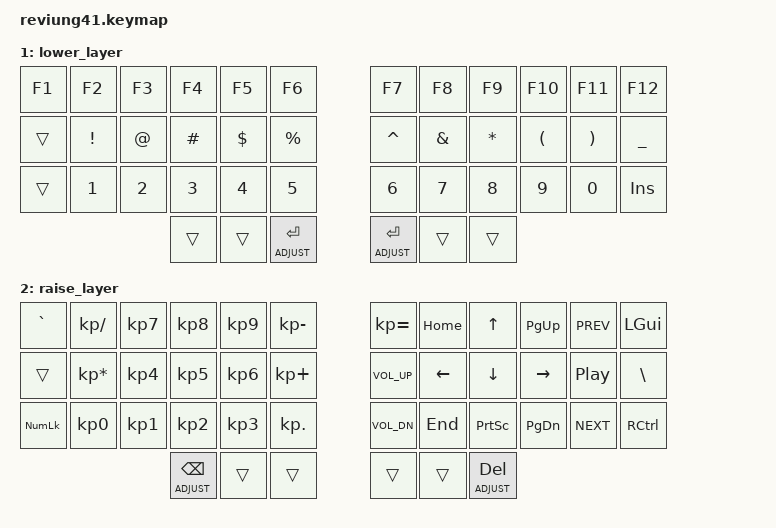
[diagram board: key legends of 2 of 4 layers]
/*
 * Copyright (c) 2020 The ZMK Contributors
 *
 * SPDX-License-Identifier: MIT
 */

#include <behaviors.dtsi>
#include <dt-bindings/zmk/keys.h>
#include <dt-bindings/zmk/bt.h>
#include <dt-bindings/zmk/rgb.h>

#define DEFAULT 0
#define LOWER   1
#define RAISE   2
#define ADJUST  3

&lt { quick_tap_ms = <200>; };
&mt { quick_tap_ms = <200>; };

/ {
        keymap {
                compatible = "zmk,keymap";

                default_layer {
                        bindings = <
   &mt LGUI ESC   &kp Q &kp W &kp E &kp R &kp T   &kp Y &kp U  &kp I     &kp O   &kp P    &mt RGUI LBKT
   &mt LCTRL TAB  &kp A &kp S &kp D &kp F &kp G   &kp H &kp J  &kp K     &kp L   &kp SEMI &kp SQT
   &kp LALT       &kp Z &kp X &kp C &kp V &kp B   &kp N &kp M  &kp COMMA &kp DOT &kp FSLH &mt RCTRL RBKT
   &lt LOWER BSPC  &mt LSHIFT SPACE &lt RAISE ENTER &mt RSHIFT SPACE &lt LOWER DEL
                        >;
                };

                lower_layer {
                        bindings = <
   &kp F1  &kp F2   &kp F3 &kp F4   &kp F5    &kp F6      &kp F7    &kp F8   &kp F9   &kp F10   &kp F11   &kp F12
   &trans  &kp EXCL &kp AT &kp HASH &kp DLLR  &kp PRCNT   &kp CARET &kp AMPS &kp STAR &kp LPAR  &kp RPAR  &kp UNDER
   &trans  &kp N1   &kp N2 &kp N3   &kp N4    &kp N5      &kp N6    &kp N7   &kp N8   &kp N9    &kp N0    &kp INS
                 &trans   &trans    &lt ADJUST ENTER      &lt ADJUST ENTER  &trans   &trans
                        >;
                };

                raise_layer {
                        bindings = <
   &kp GRAVE   &kp KP_SLASH     &kp KP_N7  &kp KP_N8  &kp KP_N9  &kp KP_MINUS    &kp KP_EQUAL  &kp HOME  &kp UP    &kp PG_UP  &kp C_PREV  &kp LGUI
   &trans      &kp KP_ASTERISK  &kp KP_N4  &kp KP_N5  &kp KP_N6  &kp KP_PLUS     &kp C_VOL_UP  &kp LEFT  &kp DOWN  &kp RIGHT  &kp C_PP    &kp BSLH
   &kp KP_NLCK &kp KP_N0        &kp KP_N1  &kp KP_N2  &kp KP_N3  &kp KP_DOT      &kp C_VOL_DN  &kp END   &kp PSCRN &kp PG_DN  &kp C_NEXT  &kp RCTRL
                    	         &lt ADJUST BSPC  &trans   &trans  &trans   &trans    &lt ADJUST DEL
                        >;
                };

                adjust_layer {
                        bindings = <
   &bt BT_CLR      &bt BT_SEL 0    &bt BT_SEL 1    &bt BT_SEL 2    &bt BT_SEL 3  &bt BT_SEL 4    &bt BT_SEL 4 &bt BT_SEL 3 &bt BT_SEL 2 &bt BT_SEL 1 &bt BT_SEL 0 &bt BT_CLR
   &rgb_ug RGB_BRI &rgb_ug RGB_SAI &rgb_ug RGB_HUI &rgb_ug RGB_EFF &none &rgb_ug RGB_TOG    &none        &none        &none        &none        &none        &none
   &rgb_ug RGB_BRD &rgb_ug RGB_SAD &rgb_ug RGB_HUD &rgb_ug RGB_EFR &none &none              &none        &none        &none        &none        &none        &none
                                                             &trans      &trans       &tog 3        &trans      &trans
                        >;
                };
        };
};
